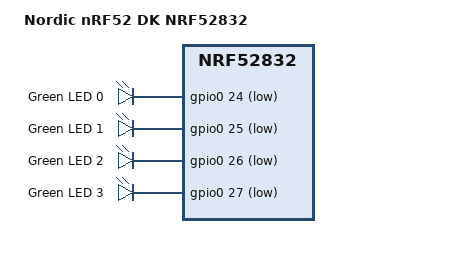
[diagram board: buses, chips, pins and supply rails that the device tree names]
/ {
	model = "Nordic nRF52 DK NRF52832";
	compatible = "nordic,nrf52-dk-nrf52832";
	leds {
		compatible = "gpio-leds";
		led0: led_0 {
			gpios = <&gpio0 24 GPIO_ACTIVE_LOW>;
			label = "Green LED 0";
		};
		led1: led_1 {
			gpios = <&gpio0 25 GPIO_ACTIVE_LOW>;
			label = "Green LED 1";
		};
		led2: led_2 {
			gpios = <&gpio0 26 GPIO_ACTIVE_LOW>;
			label = "Green LED 2";
		};
		led3: led_3 {
			gpios = <&gpio0 27 GPIO_ACTIVE_LOW>;
			label = "Green LED 3";
		};
	};
};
